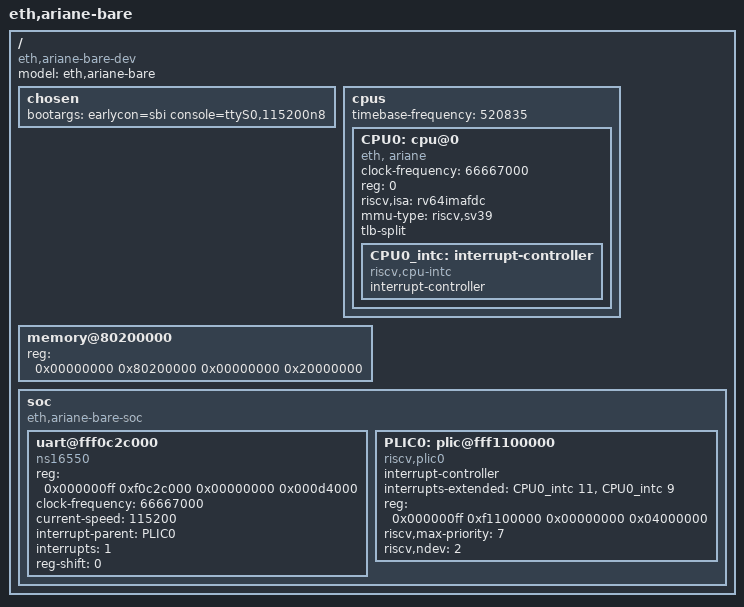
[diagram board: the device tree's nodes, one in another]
// DTS generated with gen_riscv_dts(...)
// OpenPiton + Ariane framework
// Date: Dec 01 2021 14:48:07

/dts-v1/;

/ {
    #address-cells = <2>;
    #size-cells = <2>;
    compatible = "eth,ariane-bare-dev";
    model = "eth,ariane-bare";
    // TODO: interrupt-based UART is currently very slow
    // with this configuration. this needs to be fixed.
   	chosen {		
	    bootargs = "earlycon=sbi console=ttyS0,115200n8";
	    //stdout-path = "/soc/uart0@fff0c2c000:115200n8";
    };

    cpus {
        #address-cells = <1>;
        #size-cells = <0>;
        timebase-frequency = <520835>;
    
        CPU0: cpu@0 {
            clock-frequency = <66667000>;
            device_type = "cpu";
            reg = <0>;
            status = "okay";
            compatible = "eth, ariane", "riscv";
            riscv,isa = "rv64imafdc";
            mmu-type = "riscv,sv39";
            tlb-split;
            // HLIC - hart local interrupt controller
            CPU0_intc: interrupt-controller {
                #interrupt-cells = <1>;
                interrupt-controller;
                compatible = "riscv,cpu-intc";
            };
        };     
    };
    
    memory@80200000 {
        device_type = "memory";
        reg = < 0x00000000 0x80200000 0x00000000 0x20000000 >;
    };
            
    soc {
        #address-cells = <2>;
        #size-cells = <2>;
        compatible = "eth,ariane-bare-soc", "simple-bus";
        ranges;
    
        uart@fff0c2c000 {
            compatible = "ns16550";
            reg = < 0x000000ff 0xf0c2c000 0x00000000 0x000d4000 >;
            clock-frequency = <66667000>;
            current-speed = <115200>;
            interrupt-parent = <&PLIC0>;
            interrupts = <1>;
            reg-shift = <0>; // regs are spaced on 8 bit boundary (modified from Xilinx UART16550 to be ns16550 compatible)
        };
            
        //eth: ethernet@fff0d00000 {
        //    compatible = "xlnx,xps-ethernetlite-1.00.a";
        //    device_type = "network";
        //    reg = < 0x000000ff 0xf0d00000 0x00000000 0x00100000 >;
        //    interrupt-parent = <&PLIC0>;
        //    interrupts = <2>;
        //    local-mac-address = [ 00 18 3E 02 E3 E5 ];
        //    phy-handle = <&phy0>;
        //    xlnx,duplex = <0x1>;
        //    xlnx,include-global-buffers = <0x1>;
        //    xlnx,include-internal-loopback = <0x0>;
        //    xlnx,include-mdio = <0x1>;
        //    xlnx,rx-ping-pong = <0x1>;
        //    xlnx,s-axi-id-width = <0x1>;
        //    xlnx,tx-ping-pong = <0x1>;
        //    xlnx,use-internal = <0x0>;
        //    axi_ethernetlite_0_mdio: mdio {
        //        #address-cells = <1>;
        //        #size-cells = <0>;
        //        phy0: phy@1 {
        //            compatible = "ethernet-phy-id001C.C915";
        //            device_type = "ethernet-phy";
        //            reg = <1>;
        //        };
        //    };
        //};
            
        PLIC0: plic@fff1100000 {
            #address-cells = <0>;
            #interrupt-cells = <1>;
            compatible = "riscv,plic0";
            interrupt-controller;
            interrupts-extended = <&CPU0_intc 11 &CPU0_intc 9>;
            reg = < 0x000000ff 0xf1100000 0x00000000 0x04000000 >;
            riscv,max-priority = <7>;
            riscv,ndev = <2>;
        };
            
    };
};
    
